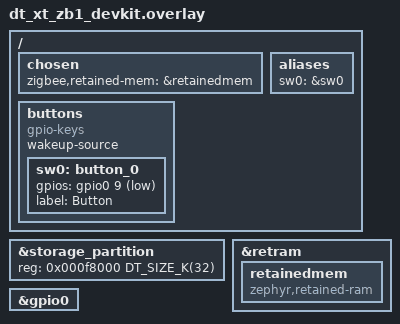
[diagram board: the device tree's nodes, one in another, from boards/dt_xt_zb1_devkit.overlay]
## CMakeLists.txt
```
# SPDX-FileCopyrightText: Copyright The Zephyr Project Contributors
# SPDX-License-Identifier: Apache-2.0
cmake_minimum_required(VERSION 3.20)
find_package(Zephyr REQUIRED HINTS $ENV{ZEPHYR_BASE})
project(switch)

target_sources(app PRIVATE
  src/main.c
  ../common/app_common.c
  ../zigbee_shell/src/app_bdb.c
)
target_compile_definitions(app PRIVATE
  APP_MODEL_ID="TL-OnOffSwitch"
  APP_POWER_SOURCE=0x03
)
target_include_directories(app PRIVATE
  ../common
  ../zigbee_shell/src
  ${ZEPHYR_BASE}/subsys/zigbee
  ${ZEPHYR_BASE}/subsys/zigbee/include
  ${ZEPHYR_BASE}/subsys/zigbee/common/includes
  ${ZEPHYR_BASE}/subsys/zigbee/platform/zephyr
)
```

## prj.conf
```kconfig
# SPDX-FileCopyrightText: Copyright The Zephyr Project Contributors
# SPDX-License-Identifier: Apache-2.0

CONFIG_ZIGBEE=y
CONFIG_ZIGBEE_ED=y
CONFIG_ZIGBEE_BDB=y
CONFIG_GPIO=y
CONFIG_ZIGBEE_ZCL=y
CONFIG_ZIGBEE_GP=n
CONFIG_ZIGBEE_OTA=n
CONFIG_ZIGBEE_WWAH=n
# k_sys_fatal_error_handler() reboots instead of spinning forever on a
# fault/assert -- required so SYSTEM_RESET() (zb_main.c) links.
CONFIG_REBOOT=y
CONFIG_NETWORKING=y
CONFIG_NET_L2_CUSTOM_IEEE802154=y
CONFIG_NET_TC_RX_COUNT=0
CONFIG_NET_IPV4=n
CONFIG_NET_IPV6=n
CONFIG_NET_UDP=n
CONFIG_NET_TCP=n
CONFIG_NET_SOCKETS=n
CONFIG_IEEE802154=y
CONFIG_IEEE802154_L2_PKT_INCL_FCS=n
CONFIG_CONSOLE=n
CONFIG_UART_CONSOLE=n
CONFIG_SERIAL=n
CONFIG_PRINTK=n
CONFIG_NVS=y
CONFIG_FLASH=y
CONFIG_FLASH_MAP=y
CONFIG_LOG=n
# The ESP32 PHY calibration alone needs about 950 bytes; boards short of RAM
# lower this in their own conf.
CONFIG_MAIN_STACK_SIZE=2048
CONFIG_SYSTEM_WORKQUEUE_STACK_SIZE=1024
# Keep the packet pools small; Zigbee consumes RX packets in its own thread.
CONFIG_NET_BUF_RX_COUNT=2
CONFIG_NET_BUF_TX_COUNT=2
CONFIG_ZIGBEE_ZCL_GROUP=y
CONFIG_ZIGBEE_ZCL_ON_OFF=y
CONFIG_ZIGBEE_ZCL_LEVEL_CTRL=y
```

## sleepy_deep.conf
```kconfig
# SPDX-FileCopyrightText: Copyright The Zephyr Project Contributors
# SPDX-License-Identifier: Apache-2.0

# Battery powered switch: deep sleep between the parent polls, ended early by a
# button that is a wakeup source. Every wakeup restarts the firmware.
CONFIG_PM=y
CONFIG_TICKLESS_KERNEL=y
CONFIG_ZIGBEE_SLEEPY_DEEP=y
```

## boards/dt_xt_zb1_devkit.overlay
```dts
/*
 * SPDX-FileCopyrightText: Copyright The Zephyr Project Contributors
 * SPDX-License-Identifier: Apache-2.0
 */

/*
 * The Zigbee NV is an NVS volume and a lookup of an absent key walks every
 * sector of it: eight sectors at the end of the flash keep the start-up, which
 * a sleepy device repeats on every wakeup, in the range of milliseconds.
 */
&storage_partition {
	reg = <0x000f8000 DT_SIZE_K(32)>;
};

/* The retention RAM keeps the outgoing frame counter through the hibernate. */
&retram {
	retainedmem: retainedmem {
		compatible = "zephyr,retained-ram";
		status = "okay";
	};
};

&gpio0 {
	status = "okay";
};

/*
 * The button connects GPIO9 to the ground. GPIO9 is the only pin of the module
 * that ends the hibernate; the pull-up flag selects the one of the hibernate
 * domain, so the button needs no resistor.
 */
/ {
	chosen {
		zigbee,retained-mem = &retainedmem;
	};

	buttons {
		compatible = "gpio-keys";
		wakeup-source;

		sw0: button_0 {
			gpios = <&gpio0 9 (GPIO_ACTIVE_LOW | GPIO_PULL_UP)>;
			label = "Button";
		};
	};

	aliases {
		sw0 = &sw0;
	};
};
```

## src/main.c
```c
/*
 * SPDX-FileCopyrightText: Copyright The Zephyr Project Contributors
 * SPDX-License-Identifier: Apache-2.0
 */
/*
 * On/Off switch: sw0 toggles the lights in range, sw1 steps their level.
 * Commands are broadcast to all rx-on-when-idle devices (0xFFFC), so the
 * sample needs no binding to control a light.
 */

#include "app_common.h"

#include <string.h>

#include "aps/aps_api.h"
#include "zbapi/zb_api.h"
#include "zcl/general/zcl_group.h"
#include "zcl/general/zcl_onoff.h"
#include "zcl/general/zcl_level.h"

#define BROADCAST_RX_ON_IDLE 0xFFFCU
#define LEVEL_STEP           50U
#define LEVEL_TRANSITION_DS  10U

static u16 out_clusters[] = {
	ZCL_CLUSTER_GEN_GROUPS,
	ZCL_CLUSTER_GEN_ON_OFF,
	ZCL_CLUSTER_GEN_LEVEL_CONTROL,
};

static u16 in_clusters[] = {
	ZCL_CLUSTER_GEN_BASIC,
	ZCL_CLUSTER_GEN_IDENTIFY,
};

static af_simple_descriptor_t simple_desc = {
	.app_profile_id = APP_HA_PROFILE_ID,
	.app_dev_id = 0x0000U, /* On/Off Switch */
	.endpoint = APP_ENDPOINT,
	.app_dev_ver = 1U,
	.reserved = 0U,
	.app_in_cluster_count = ARRAY_SIZE(in_clusters),
	.app_in_cluster_lst = in_clusters,
	.app_out_cluster_count = ARRAY_SIZE(out_clusters),
	.app_out_cluster_lst = out_clusters,
};

/* Client clusters have no attributes of their own. */
static zcl_specClusterInfo_t clusters[APP_COMMON_CLUSTER_NUM + 3U];

static void dst_broadcast(epInfo_t *dst)
{
	memset(dst, 0, sizeof(*dst));
	dst->dstAddrMode = APS_SHORT_DSTADDR_WITHEP;
	dst->dstAddr.shortAddr = BROADCAST_RX_ON_IDLE;
	dst->dstEp = APP_ENDPOINT;
	dst->profileId = APP_HA_PROFILE_ID;
}

static void button_cb(uint8_t idx, bool pressed)
{
	static u8 level;
	epInfo_t dst;

	if (!pressed || !zb_isDeviceJoinedNwk()) {
		return;
	}

	dst_broadcast(&dst);

	if (idx == 0U) {
		zcl_onOff_toggleCmd(APP_ENDPOINT, &dst, TRUE);
	} else {
		moveToLvl_t move = {
			.transitionTime = LEVEL_TRANSITION_DS,
		};

		level += LEVEL_STEP;
		if (level > ZCL_LEVEL_ATTR_MAX_LEVEL) {
			level = ZCL_LEVEL_ATTR_MIN_LEVEL;
		}
		move.level = level;
		zcl_level_move2levelCmd(APP_ENDPOINT, &dst, TRUE, &move);
	}
}

void app_device_register(void)
{
	app_common_clusters(clusters);

	clusters[2] = (zcl_specClusterInfo_t){
		.clusterId = ZCL_CLUSTER_GEN_GROUPS,
		.clusterRegisterFunc = zcl_group_register,
	};
	clusters[3] = (zcl_specClusterInfo_t){
		.clusterId = ZCL_CLUSTER_GEN_ON_OFF,
		.clusterRegisterFunc = zcl_onOff_register,
	};
	clusters[4] = (zcl_specClusterInfo_t){
		.clusterId = ZCL_CLUSTER_GEN_LEVEL_CONTROL,
		.clusterRegisterFunc = zcl_level_register,
	};

	app_endpoint_register(&simple_desc, clusters, ARRAY_SIZE(clusters), NULL);
	app_buttons_init(button_cb);
}
```
